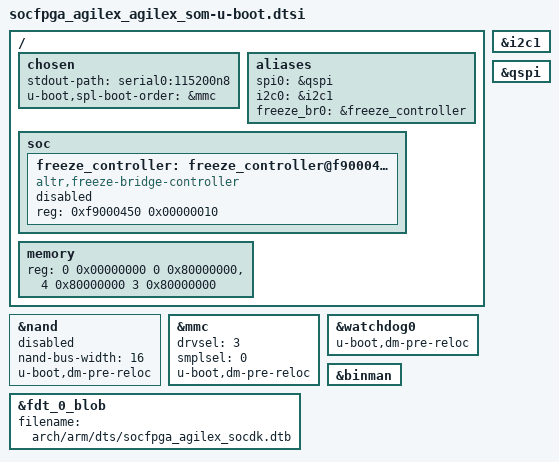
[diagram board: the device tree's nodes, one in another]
// SPDX-License-Identifier: GPL-2.0+
/*
 * U-Boot additions
 *
 * Copyright (C) 2019-2022 Intel Corporation <www.intel.com>
 */

#include "socfpga_agilex-u-boot.dtsi"

/{
	chosen {
		stdout-path = "serial0:115200n8";
		u-boot,spl-boot-order = &mmc;
	};

	aliases {
		spi0 = &qspi;
		i2c0 = &i2c1;
		freeze_br0 = &freeze_controller;
	};

	soc {
		freeze_controller: freeze_controller@f9000450 {
			compatible = "altr,freeze-bridge-controller";
			reg = <0xf9000450 0x00000010>;
			status = "disabled";
		};
	};

	memory {
		/* 16GB */
		reg = <0 0x00000000 0 0x80000000>,
		      <4 0x80000000 3 0x80000000>;
	};
};



&i2c1 {
	status = "okay";
};

&nand {
	status = "disabled";
	nand-bus-width = <16>;
	u-boot,dm-pre-reloc;
};

&mmc {
	drvsel = <3>;
	smplsel = <0>;
	u-boot,dm-pre-reloc;
};

&qspi {
	status = "okay";
};

&watchdog0 {
	u-boot,dm-pre-reloc;
};

#if !defined(CONFIG_SOCFPGA_SECURE_VAB_AUTH)
&fdt_0_blob {
	filename = "arch/arm/dts/socfpga_agilex_socdk.dtb";
};


&binman {
	/delete-node/ kernel;
};
#endif

